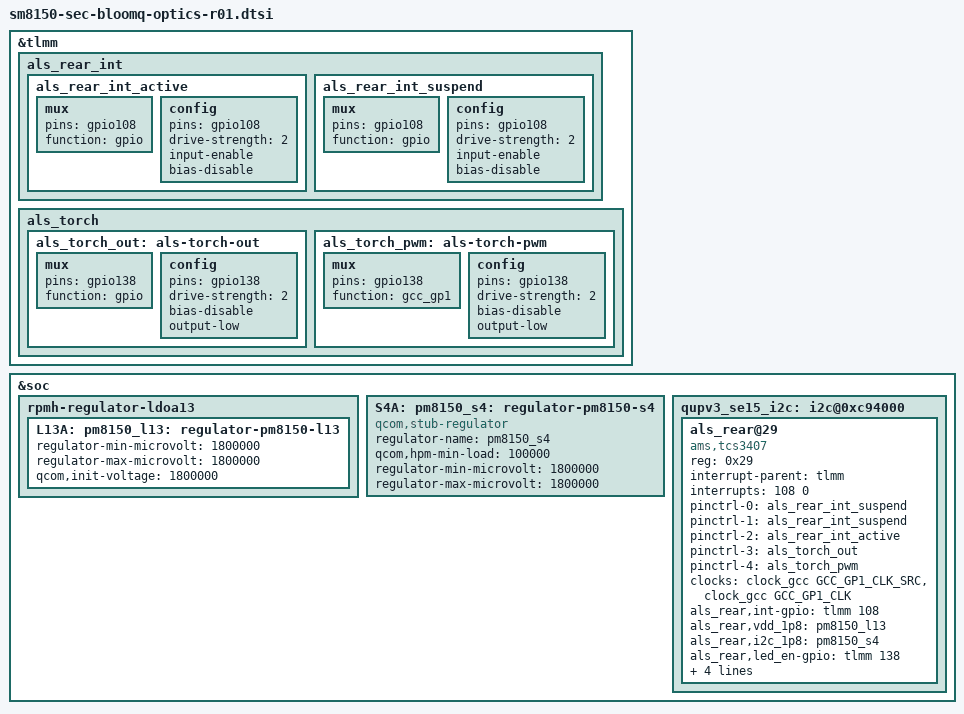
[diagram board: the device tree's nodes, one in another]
/*
 * Copyright (c) 2018, The Linux Foundation. All rights reserved.
 *
 * This program is free software; you can redistribute it and/or modify
 * it under the terms of the GNU General Public License version 2 and
 * only version 2 as published by the Free Software Foundation.
 *
 * This program is distributed in the hope that it will be useful,
 * but WITHOUT ANY WARRANTY; without even the implied warranty of
 * MERCHANTABILITY or FITNESS FOR A PARTICULAR PURPOSE.  See the
 * GNU General Public License for more details.
 */

&tlmm {
	als_rear_int {
		als_rear_int_active: als_rear_int_active {
			mux {
				pins = "gpio108";
				function = "gpio";
			};

			config {
				pins = "gpio108";
				drive-strength = <2>;
				input-enable;
				bias-disable;
			};
		};
		als_rear_int_suspend: als_rear_int_suspend {
			mux {
				pins = "gpio108";
				function = "gpio";
			};

			config {
				pins = "gpio108";
				drive-strength = <2>;
				input-enable;
				bias-disable;
			};
		};
	};

	als_torch {
		als_torch_out: als-torch-out {
			mux {
				pins = "gpio138";
				function = "gpio";
			};
		
			config {
				pins = "gpio138";
				drive-strength = <2>;   /* 16 mA */
				bias-disable;
				output-low;

			};
		};
		
		als_torch_pwm: als-torch-pwm {
			mux {
				pins = "gpio138";
				function = "gcc_gp1";
			};
		
			config {
				pins = "gpio138";
				drive-strength = <2>;   /* 16 mA */
				bias-disable;
				output-low;
			};
		};
	};
};

&soc { 
	rpmh-regulator-ldoa13 {
		L13A: pm8150_l13: regulator-pm8150-l13 {
			regulator-min-microvolt = <1800000>;
			regulator-max-microvolt = <1800000>;
			qcom,init-voltage = <1800000>;
		};
	};

 	S4A: pm8150_s4: regulator-pm8150-s4 {
		compatible = "qcom,stub-regulator";
		regulator-name = "pm8150_s4";
		qcom,hpm-min-load = <100000>;
		regulator-min-microvolt = <1800000>;
		regulator-max-microvolt = <1800000>;
 	};

	qupv3_se15_i2c: i2c@0xc94000 {
		status = "ok";
		als_rear@29 {
			compatible = "ams,tcs3407";
			reg = <0x29>;
			interrupt-parent = <&tlmm>;
			interrupts = <108 0>;
			pinctrl-names = "sleep", "default", "idle", "torch_out", "torch_pwm";
			pinctrl-0 = <&als_rear_int_suspend>;
			pinctrl-1 = <&als_rear_int_suspend>;
			pinctrl-2 = <&als_rear_int_active>;
			pinctrl-3 = <&als_torch_out>;
			pinctrl-4 = <&als_torch_pwm>;
			clocks = <&clock_gcc GCC_GP1_CLK_SRC>, <&clock_gcc GCC_GP1_CLK >; 
			clock-names = "gpio_pwm_default-clk", "gpio_pwm_default-clk-cbcr";
			als_rear,int-gpio = <&tlmm 108 0x00>;
			als_rear,vdd_1p8 = "pm8150_l13";  /* LDO13A */
			als_rear,i2c_1p8 = "pm8150_s4";  /* LDO S4 */
			als_rear,led_en-gpio = <&tlmm 138 0x00>;
			als_rear,gain_max = <0xbc>;
			als_rear,ir_spec = <0 500000 0 500000>;
			als_rear,clear_spec = <0 500000 0 500000>;
			als_rear,icratio_spec = <0 10000 0 10000>;
		};
	};
};
